# SMS0_SECCTRL_0_SEC register map
Vendor: Texas Instruments
Peripheral module from a debugger description file (folder am62P).
Registers are 32-bit, read-write, reset 0x0 unless marked. A register's access mark holds for its fields unless they carry their own. Offsets are as the file gives them; lines under a group give offsets from that group; [hi:lo] are bit positions; {n}, {i} and the like mark numbered series; 'fields as' and 'values as' point back to an identical list; <NAME> marks a mode.

## SMS0_SECCTRL_0_SEC
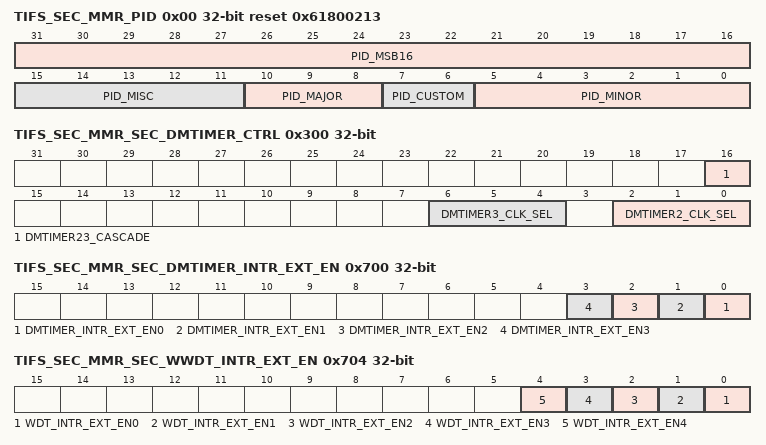
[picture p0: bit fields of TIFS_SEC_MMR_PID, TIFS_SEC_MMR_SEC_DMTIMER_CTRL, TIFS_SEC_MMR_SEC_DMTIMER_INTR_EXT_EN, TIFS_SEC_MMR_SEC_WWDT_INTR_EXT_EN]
0x00 TIFS_SEC_MMR_PID ro reset 0x61800213
  [31:16] PID_MSB16, [15:11] PID_MISC, [10:8] PID_MAJOR, [7:6] PID_CUSTOM, [5:0] PID_MINOR
0x20 TIFS_SEC_MMR_LOCK0_KICK0
  [31:0] LOCK0_KICK0 — - KICK0 component
0x24 TIFS_SEC_MMR_LOCK0_KICK1
  [31:0] LOCK0_KICK1 — - KICK1 component
0x100 TIFS_SEC_MMR_SEC_ROM_START_ADDR ro
  [31:0] SEC_ROM_START_ADDR
0x104 TIFS_SEC_MMR_SEC_ROM_END_ADDR ro
  [31:0] SEC_ROM_END_ADDR
0x200 TIFS_SEC_MMR_SEC_ACTIVE
  [0] SECURITY_ACTIVE
0x210 TIFS_SEC_MMR_SEC_SOC_WARM_RESET
  [31:0] WARM_RESET_CODE
0x220 TIFS_SEC_MMR_SEC_SOC_COLD_RESET
  [31:0] COLD_RESET_CODE
0x300 TIFS_SEC_MMR_SEC_DMTIMER_CTRL
  [16] DMTIMER23_CASCADE, [6:4] DMTIMER3_CLK_SEL, [2:0] DMTIMER2_CLK_SEL
0x400 TIFS_SEC_MMR_SEC_EMU_WAIT_IN_RESET_REQ ro
  [0] DBG_WAIT_N_RST
0x420 TIFS_SEC_MMR_SEC_SMS_TIFS_JUMP_MAGIC_NUM
  [31:0] JUMP_MAGIC_NUM
0x430 TIFS_SEC_MMR_SEC_SMS_TIFS_JUMP_ADDRESS
  [31:0] JUMP_ADDRESS
0x500 TIFS_SEC_MMR_SEC_FW_EXP_LOWER ro
  [31:0] SEC_FW_EXP_LOW_VAL0
0x504 TIFS_SEC_MMR_SEC_FW_EXP_UPPER ro
  [31:0] SEC_FW_EXT_UPPER_VAL0
0x600 TIFS_SEC_MMR_SEC_CTRL_OUT0_VAL ro
  [31:0] SEC_CTRL_OUT_VAL0
0x604 TIFS_SEC_MMR_SEC_CTRL_OUT0 access not given
  [31:0] SEC_CTRL_OUT0 — (access R/W1TS)
0x608 TIFS_SEC_MMR_SEC_CTRL_OUT0_CLR access not given
  [31:0] SEC_CTRL_OUT0_CLR — (access R/W1TC)
0x60C TIFS_SEC_MMR_SEC_STS_IN0 ro
  [31:0] SEC_STS_IN0
0x700 TIFS_SEC_MMR_SEC_DMTIMER_INTR_EXT_EN
  [n] DMTIMER_INTR_EXT_EN{n} (n=0..3)
0x704 TIFS_SEC_MMR_SEC_WWDT_INTR_EXT_EN
  [n] WDT_INTR_EXT_EN{n} (n=0..4)
0x708 TIFS_SEC_MMR_SEC_DEBUG_INTR_EXT_EN
  [0] DBG_AUTH_INTR_EXT_EN0
0x70C TIFS_SEC_MMR_SEC_ECC_AGGR_INTR_EXT_EN
  [0] ECC_AGGR_INTR_EXT_EN0
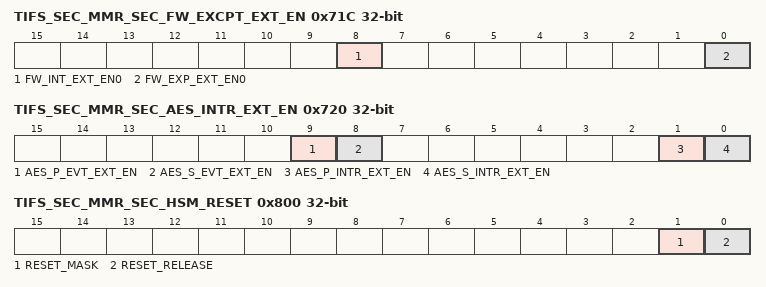
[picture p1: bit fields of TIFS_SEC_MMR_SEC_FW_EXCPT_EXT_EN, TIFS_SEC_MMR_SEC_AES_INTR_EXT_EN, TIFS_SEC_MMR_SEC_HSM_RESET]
0x71C TIFS_SEC_MMR_SEC_FW_EXCPT_EXT_EN
  [8] FW_INT_EXT_EN0, [0] FW_EXP_EXT_EN0
0x720 TIFS_SEC_MMR_SEC_AES_INTR_EXT_EN
  [9] AES_P_EVT_EXT_EN, [8] AES_S_EVT_EXT_EN, [1] AES_P_INTR_EXT_EN, [0] AES_S_INTR_EXT_EN
0x724 TIFS_SEC_MMR_SEC_RAT_INTR_EXT_EN
  [0] RAT_INTR_EXT_EN
0x728 TIFS_SEC_MMR_SEC_IA_INTR_EXT_EN
  [0] IA_INTR_EXT_EN
0x800 TIFS_SEC_MMR_SEC_HSM_RESET
  [1] RESET_MASK, [0] RESET_RELEASE
0x804 TIFS_SEC_MMR_SEC_HSM_DEBUG
  [3:0] DBGEN
{0x900+4i} TIFS_SEC_MMR_SEC_SPARE_REG{i} (i=0..3)
  [31:0] SEC_SPARE{i}
